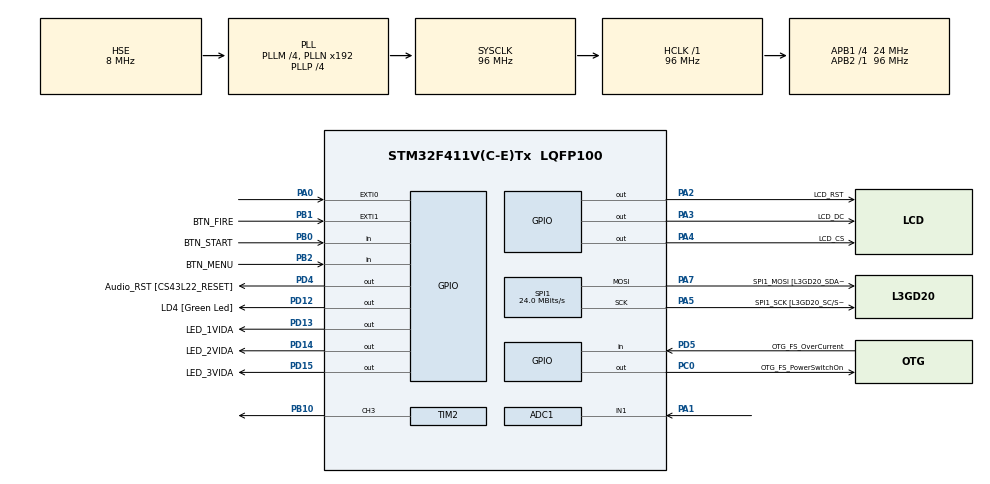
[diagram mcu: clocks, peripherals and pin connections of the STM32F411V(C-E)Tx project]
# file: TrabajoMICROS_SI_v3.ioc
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ADC1.Channel-0\#ChannelRegularConversion=ADC_CHANNEL_1
ADC1.ContinuousConvMode=ENABLE
ADC1.NbrOfConversionFlag=1
ADC1.Rank-0\#ChannelRegularConversion=1
ADC1.SamplingTime-0\#ChannelRegularConversion=ADC_SAMPLETIME_3CYCLES
ADC1.master=1
Dma.Request0=SPI1_TX
Dma.SPI1_TX.0.Direction=DMA_MEMORY_TO_PERIPH
Dma.SPI1_TX.0.FIFOMode=DMA_FIFOMODE_DISABLE
Dma.SPI1_TX.0.Instance=DMA2_Stream2
Dma.SPI1_TX.0.MemDataAlignment=DMA_MDATAALIGN_BYTE
Dma.SPI1_TX.0.MemInc=DMA_MINC_ENABLE
Dma.SPI1_TX.0.Mode=DMA_NORMAL
Dma.SPI1_TX.0.PeriphDataAlignment=DMA_PDATAALIGN_BYTE
Dma.SPI1_TX.0.PeriphInc=DMA_PINC_DISABLE
Dma.SPI1_TX.0.Priority=DMA_PRIORITY_HIGH
Mcu.Family=STM32F4
Mcu.Name=STM32F411V(C-E)Tx
Mcu.Package=LQFP100
NVIC.DMA2_Stream2_IRQn=true\:0\:0\:false\:false\:true\:false\:true\:true
NVIC.EXTI1_IRQn=true\:0\:0\:false\:false\:true\:true\:true\:true
NVIC.PriorityGroup=NVIC_PRIORITYGROUP_0
PA0-WKUP.GPIO_ModeDefaultEXTI=GPIO_MODE_EVT_RISING
PA0-WKUP.Signal=GPXTI0
PA1.Signal=ADCx_IN1
PA13.GPIO_Label=SWDIO
PA13.Mode=Serial_Wire
PA13.Signal=SYS_JTMS-SWDIO
PA14.GPIO_Label=SWCLK
PA14.Mode=Serial_Wire
PA14.Signal=SYS_JTCK-SWCLK
PA2.GPIO_Label=LCD_RST
PA2.Signal=GPIO_Output
PA3.GPIO_Label=LCD_DC
PA3.Signal=GPIO_Output
PA4.GPIO_Label=LCD_CS
PA4.Signal=GPIO_Output
PA5.GPIO_Label=SPI1_SCK [L3GD20_SC/SPC]
PA5.Mode=TX_Only_Simplex_Unidirect_Master
PA5.Signal=SPI1_SCK
PA6.GPIO_Label=SPI1_MISO [L3GD20_AS0/SDO]
PA6.Signal=SPI1_MISO
PA7.GPIO_Label=SPI1_MOSI [L3GD20_SDA/SDI/SDO]
PA7.Mode=TX_Only_Simplex_Unidirect_Master
PA7.Signal=SPI1_MOSI
PB0.GPIO_Label=BTN_START
PB0.GPIO_PuPd=GPIO_PULLUP
PB0.Signal=GPIO_Input
PB1.GPIO_Label=BTN_FIRE
PB1.GPIO_PuPd=GPIO_PULLUP
PB1.Signal=GPXTI1
PB10.Signal=S_TIM2_CH3
PB2.GPIO_Label=BTN_MENU
PB2.GPIO_PuPd=GPIO_PULLUP
PB2.Signal=GPIO_Input
PB3.GPIO_Label=SWO
PB3.Signal=SYS_JTDO-SWO
PC0.GPIO_Label=OTG_FS_PowerSwitchOn
PC0.PinState=GPIO_PIN_SET
PC0.Signal=GPIO_Output
PC14-OSC32_IN.GPIO_Label=PC14-OSC32_IN
PC14-OSC32_IN.Mode=LSE-External-Oscillator
PC14-OSC32_IN.Signal=RCC_OSC32_IN
PC15-OSC32_OUT.GPIO_Label=PC15-OSC32_OUT
PC15-OSC32_OUT.Mode=LSE-External-Oscillator
PC15-OSC32_OUT.Signal=RCC_OSC32_OUT
PD12.GPIO_Label=LD4 [Green Led]
PD12.GPIO_PuPd=GPIO_NOPULL
PD12.GPIO_Speed=GPIO_SPEED_FREQ_LOW
PD12.Signal=GPIO_Output
PD13.GPIO_Label=LED_1VIDA
PD13.GPIO_PuPd=GPIO_NOPULL
PD13.GPIO_Speed=GPIO_SPEED_FREQ_LOW
PD13.Signal=GPIO_Output
PD14.GPIO_Label=LED_2VIDA
PD14.GPIO_PuPd=GPIO_NOPULL
PD14.GPIO_Speed=GPIO_SPEED_FREQ_LOW
PD14.Signal=GPIO_Output
PD15.GPIO_Label=LED_3VIDA
PD15.GPIO_PuPd=GPIO_NOPULL
PD15.GPIO_Speed=GPIO_SPEED_FREQ_LOW
PD15.Signal=GPIO_Output
PD4.GPIO_Label=Audio_RST [CS43L22_RESET]
PD4.Signal=GPIO_Output
PD5.GPIO_Label=OTG_FS_OverCurrent
PD5.Signal=GPIO_Input
PH0\ -\ OSC_IN.GPIO_Label=PH0-OSC_IN
PH0\ -\ OSC_IN.Mode=HSE-External-Oscillator
PH0\ -\ OSC_IN.Signal=RCC_OSC_IN
PH1\ -\ OSC_OUT.GPIO_Label=PH1-OSC_OUT
PH1\ -\ OSC_OUT.Mode=HSE-External-Oscillator
PH1\ -\ OSC_OUT.Signal=RCC_OSC_OUT
ProjectManager.HeapSize=0x200
ProjectManager.StackSize=0x400
ProjectManager.TargetToolchain=STM32CubeIDE
RCC.48MHZClocksFreq_Value=48000000
RCC.AHBFreq_Value=96000000
RCC.APB1CLKDivider=RCC_HCLK_DIV4
RCC.APB1Freq_Value=24000000
RCC.APB1TimFreq_Value=48000000
RCC.APB2Freq_Value=96000000
RCC.APB2TimFreq_Value=96000000
RCC.CortexFreq_Value=96000000
RCC.HCLKFreq_Value=96000000
RCC.HSE_VALUE=8000000
RCC.HSI_VALUE=16000000
RCC.PLLI2SM=5
RCC.PLLI2SN=200
RCC.PLLM=4
RCC.PLLP=RCC_PLLP_DIV4
RCC.PLLQ=8
RCC.PLLSourceVirtual=RCC_PLLSOURCE_HSE
RCC.SYSCLKFreq_VALUE=96000000
RCC.SYSCLKSource=RCC_SYSCLKSOURCE_PLLCLK
RCC.VCOOutputFreq_Value=384000000
SH.ADCx_IN1.0=ADC1_IN1,IN1
SH.S_TIM2_CH3.0=TIM2_CH3,PWM Generation3 CH3
SPI1.BaudRatePrescaler=SPI_BAUDRATEPRESCALER_4
SPI1.CalculateBaudRate=24.0 MBits/s
SPI1.Direction=SPI_DIRECTION_2LINES
SPI1.Mode=SPI_MODE_MASTER
SPI1.VirtualType=VM_MASTER
TIM2.Channel-PWM\ Generation3\ CH3=TIM_CHANNEL_3
board=STM32F411E-DISCO

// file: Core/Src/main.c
/* USER CODE BEGIN Header */
/** @file           : main.c
  * @brief          : Main program body
  ******************************************************************************
  * @attention
  *
  * Copyright (c) 2026 STMicroelectronics.
  * All rights reserved.
  *
  * This software is licensed under terms that can be found in the LICENSE file
  * in the root directory of this software component.
  * If no LICENSE file comes with this software, it is provided AS-IS.
  *
  ******************************************************************************
  */
/* USER CODE END Header */
#include "main.h"

/* USER CODE BEGIN Includes */
#include "st7796_lcd.h"
#include "peripherals.h"
#include "game_engine.h"
/* USER CODE END Includes */

ADC_HandleTypeDef hadc1;

SPI_HandleTypeDef hspi1;
DMA_HandleTypeDef hdma_spi1_tx;

TIM_HandleTypeDef htim2;

void SystemClock_Config(void);
static void MX_GPIO_Init(void);
static void MX_DMA_Init(void);
static void MX_SPI1_Init(void);
static void MX_ADC1_Init(void);
static void MX_TIM2_Init(void);

int main(void)
{

  /* MCU Configuration--------------------------------------------------------*/

  /* Reset of all peripherals, Initializes the Flash interface and the Systick. */
  HAL_Init();

  /* Configure the system clock */
  SystemClock_Config();

  /* Initialize all configured peripherals */
  MX_GPIO_Init();
  MX_DMA_Init();
  MX_SPI1_Init();
  MX_ADC1_Init();
  MX_TIM2_Init();
  /* USER CODE BEGIN 2 */

    // Inicializamos el motor del juego y la pantalla
    Game_Init();

  /* USER CODE END 2 */

  /* Infinite loop */
  /* USER CODE BEGIN WHILE */
  while (1)
  {
	  Game_Update();

    /* USER CODE END WHILE */

  }
}

void SystemClock_Config(void)
{
  RCC_OscInitTypeDef RCC_OscInitStruct = {0};
  RCC_ClkInitTypeDef RCC_ClkInitStruct = {0};

  /** Configure the main internal regulator output voltage
  */
  __HAL_RCC_PWR_CLK_ENABLE();
  __HAL_PWR_VOLTAGESCALING_CONFIG(PWR_REGULATOR_VOLTAGE_SCALE1);

  /** Initializes the RCC Oscillators according to the specified parameters
  * in the RCC_OscInitTypeDef structure.
  */
  RCC_OscInitStruct.OscillatorType = RCC_OSCILLATORTYPE_HSE;
  RCC_OscInitStruct.HSEState = RCC_HSE_ON;
  RCC_OscInitStruct.PLL.PLLState = RCC_PLL_ON;
  RCC_OscInitStruct.PLL.PLLSource = RCC_PLLSOURCE_HSE;
  RCC_OscInitStruct.PLL.PLLM = 4;
  RCC_OscInitStruct.PLL.PLLN = 192;
  RCC_OscInitStruct.PLL.PLLP = RCC_PLLP_DIV4;
  RCC_OscInitStruct.PLL.PLLQ = 8;
  if (HAL_RCC_OscConfig(&RCC_OscInitStruct) != HAL_OK)
  {
    Error_Handler();
  }

  /** Initializes the CPU, AHB and APB buses clocks
  */
  RCC_ClkInitStruct.ClockType = RCC_CLOCKTYPE_HCLK|RCC_CLOCKTYPE_SYSCLK
                              |RCC_CLOCKTYPE_PCLK1|RCC_CLOCKTYPE_PCLK2;
  RCC_ClkInitStruct.SYSCLKSource = RCC_SYSCLKSOURCE_PLLCLK;
  RCC_ClkInitStruct.AHBCLKDivider = RCC_SYSCLK_DIV1;
  RCC_ClkInitStruct.APB1CLKDivider = RCC_HCLK_DIV4;
  RCC_ClkInitStruct.APB2CLKDivider = RCC_HCLK_DIV1;

  if (HAL_RCC_ClockConfig(&RCC_ClkInitStruct, FLASH_LATENCY_3) != HAL_OK)
  {
    Error_Handler();
  }
}

static void MX_ADC1_Init(void)
{

  ADC_ChannelConfTypeDef sConfig = {0};

  /** Configure the global features of the ADC (Clock, Resolution, Data Alignment and number of conversion)
  */
  hadc1.Instance = ADC1;
  hadc1.Init.ClockPrescaler = ADC_CLOCK_SYNC_PCLK_DIV4;
  hadc1.Init.Resolution = ADC_RESOLUTION_12B;
  hadc1.Init.ScanConvMode = DISABLE;
  hadc1.Init.ContinuousConvMode = ENABLE;
  hadc1.Init.DiscontinuousConvMode = DISABLE;
  hadc1.Init.ExternalTrigConvEdge = ADC_EXTERNALTRIGCONVEDGE_NONE;
  hadc1.Init.ExternalTrigConv = ADC_SOFTWARE_START;
  hadc1.Init.DataAlign = ADC_DATAALIGN_RIGHT;
  hadc1.Init.NbrOfConversion = 1;
  hadc1.Init.DMAContinuousRequests = DISABLE;
  hadc1.Init.EOCSelection = ADC_EOC_SINGLE_CONV;
  if (HAL_ADC_Init(&hadc1) != HAL_OK)
  {
    Error_Handler();
  }

  /** Configure for the selected ADC regular channel its corresponding rank in the sequencer and its sample time.
  */
  sConfig.Channel = ADC_CHANNEL_1;
  sConfig.Rank = 1;
  sConfig.SamplingTime = ADC_SAMPLETIME_3CYCLES;
  if (HAL_ADC_ConfigChannel(&hadc1, &sConfig) != HAL_OK)
  {
    Error_Handler();
  }

}

static void MX_SPI1_Init(void)
{

  /* SPI1 parameter configuration*/
  hspi1.Instance = SPI1;
  hspi1.Init.Mode = SPI_MODE_MASTER;
  hspi1.Init.Direction = SPI_DIRECTION_2LINES;
  hspi1.Init.DataSize = SPI_DATASIZE_8BIT;
  hspi1.Init.CLKPolarity = SPI_POLARITY_LOW;
  hspi1.Init.CLKPhase = SPI_PHASE_1EDGE;
  hspi1.Init.NSS = SPI_NSS_SOFT;
  hspi1.Init.BaudRatePrescaler = SPI_BAUDRATEPRESCALER_4;
  hspi1.Init.FirstBit = SPI_FIRSTBIT_MSB;
  hspi1.Init.TIMode = SPI_TIMODE_DISABLE;
  hspi1.Init.CRCCalculation = SPI_CRCCALCULATION_DISABLE;
  hspi1.Init.CRCPolynomial = 10;
  if (HAL_SPI_Init(&hspi1) != HAL_OK)
  {
    Error_Handler();
  }

}

static void MX_TIM2_Init(void)
{

  TIM_MasterConfigTypeDef sMasterConfig = {0};
  TIM_OC_InitTypeDef sConfigOC = {0};

  htim2.Instance = TIM2;
  htim2.Init.Prescaler = 0;
  htim2.Init.CounterMode = TIM_COUNTERMODE_UP;
  htim2.Init.Period = 4294967295;
  htim2.Init.ClockDivision = TIM_CLOCKDIVISION_DIV1;
  htim2.Init.AutoReloadPreload = TIM_AUTORELOAD_PRELOAD_DISABLE;
  if (HAL_TIM_PWM_Init(&htim2) != HAL_OK)
  {
    Error_Handler();
  }
  sMasterConfig.MasterOutputTrigger = TIM_TRGO_RESET;
  sMasterConfig.MasterSlaveMode = TIM_MASTERSLAVEMODE_DISABLE;
  if (HAL_TIMEx_MasterConfigSynchronization(&htim2, &sMasterConfig) != HAL_OK)
  {
    Error_Handler();
  }
  sConfigOC.OCMode = TIM_OCMODE_PWM1;
  sConfigOC.Pulse = 0;
  sConfigOC.OCPolarity = TIM_OCPOLARITY_HIGH;
  sConfigOC.OCFastMode = TIM_OCFAST_DISABLE;
  if (HAL_TIM_PWM_ConfigChannel(&htim2, &sConfigOC, TIM_CHANNEL_3) != HAL_OK)
  {
    Error_Handler();
  }
  HAL_TIM_MspPostInit(&htim2);

}

static void MX_DMA_Init(void)
{

  /* DMA controller clock enable */
  __HAL_RCC_DMA2_CLK_ENABLE();

  /* DMA interrupt init */
  /* DMA2_Stream2_IRQn interrupt configuration */
  HAL_NVIC_SetPriority(DMA2_Stream2_IRQn, 0, 0);
  HAL_NVIC_EnableIRQ(DMA2_Stream2_IRQn);

}

static void MX_GPIO_Init(void)
{
  GPIO_InitTypeDef GPIO_InitStruct = {0};

  /* GPIO Ports Clock Enable */
  __HAL_RCC_GPIOC_CLK_ENABLE();
  __HAL_RCC_GPIOH_CLK_ENABLE();
  __HAL_RCC_GPIOA_CLK_ENABLE();
  __HAL_RCC_GPIOB_CLK_ENABLE();
  __HAL_RCC_GPIOD_CLK_ENABLE();

  /*Configure GPIO pin Output Level */
  HAL_GPIO_WritePin(OTG_FS_PowerSwitchOn_GPIO_Port, OTG_FS_PowerSwitchOn_Pin, GPIO_PIN_SET);

  /*Configure GPIO pin Output Level */
  HAL_GPIO_WritePin(GPIOA, LCD_RST_Pin|LCD_DC_Pin|LCD_CS_Pin, GPIO_PIN_RESET);

  /*Configure GPIO pin Output Level */
  HAL_GPIO_WritePin(GPIOD, LD4_Pin|LED_1VIDA_Pin|LED_2VIDA_Pin|LED_3VIDA_Pin
                          |Audio_RST_Pin, GPIO_PIN_RESET);

  /*Configure GPIO pin : OTG_FS_PowerSwitchOn_Pin */
  GPIO_InitStruct.Pin = OTG_FS_PowerSwitchOn_Pin;
  GPIO_InitStruct.Mode = GPIO_MODE_OUTPUT_PP;
  GPIO_InitStruct.Pull = GPIO_NOPULL;
  GPIO_InitStruct.Speed = GPIO_SPEED_FREQ_LOW;
  HAL_GPIO_Init(OTG_FS_PowerSwitchOn_GPIO_Port, &GPIO_InitStruct);

  /*Configure GPIO pin : PA0 */
  GPIO_InitStruct.Pin = GPIO_PIN_0;
  GPIO_InitStruct.Mode = GPIO_MODE_EVT_RISING;
  GPIO_InitStruct.Pull = GPIO_NOPULL;
  HAL_GPIO_Init(GPIOA, &GPIO_InitStruct);

  /*Configure GPIO pins : LCD_RST_Pin LCD_DC_Pin LCD_CS_Pin */
  GPIO_InitStruct.Pin = LCD_RST_Pin|LCD_DC_Pin|LCD_CS_Pin;
  GPIO_InitStruct.Mode = GPIO_MODE_OUTPUT_PP;
  GPIO_InitStruct.Pull = GPIO_NOPULL;
  GPIO_InitStruct.Speed = GPIO_SPEED_FREQ_LOW;
  HAL_GPIO_Init(GPIOA, &GPIO_InitStruct);

  /*Configure GPIO pins : BTN_START_Pin BTN_MENU_Pin */
  GPIO_InitStruct.Pin = BTN_START_Pin|BTN_MENU_Pin;
  GPIO_InitStruct.Mode = GPIO_MODE_INPUT;
  GPIO_InitStruct.Pull = GPIO_PULLUP;
  HAL_GPIO_Init(GPIOB, &GPIO_InitStruct);

  /*Configure GPIO pin : BTN_FIRE_Pin */
  GPIO_InitStruct.Pin = BTN_FIRE_Pin;
  GPIO_InitStruct.Mode = GPIO_MODE_IT_RISING;
  GPIO_InitStruct.Pull = GPIO_PULLUP;
  HAL_GPIO_Init(BTN_FIRE_GPIO_Port, &GPIO_InitStruct);

  /*Configure GPIO pins : LD4_Pin LED_1VIDA_Pin LED_2VIDA_Pin LED_3VIDA_Pin
                           Audio_RST_Pin */
  GPIO_InitStruct.Pin = LD4_Pin|LED_1VIDA_Pin|LED_2VIDA_Pin|LED_3VIDA_Pin
                          |Audio_RST_Pin;
  GPIO_InitStruct.Mode = GPIO_MODE_OUTPUT_PP;
  GPIO_InitStruct.Pull = GPIO_NOPULL;
  GPIO_InitStruct.Speed = GPIO_SPEED_FREQ_LOW;
  HAL_GPIO_Init(GPIOD, &GPIO_InitStruct);

  /*Configure GPIO pin : OTG_FS_OverCurrent_Pin */
  GPIO_InitStruct.Pin = OTG_FS_OverCurrent_Pin;
  GPIO_InitStruct.Mode = GPIO_MODE_INPUT;
  GPIO_InitStruct.Pull = GPIO_NOPULL;
  HAL_GPIO_Init(OTG_FS_OverCurrent_GPIO_Port, &GPIO_InitStruct);

  /* EXTI interrupt init*/
  HAL_NVIC_SetPriority(EXTI1_IRQn, 0, 0);
  HAL_NVIC_EnableIRQ(EXTI1_IRQn);

}

void Error_Handler(void)
{
  __disable_irq();
  while (1)
  {
  }
}
